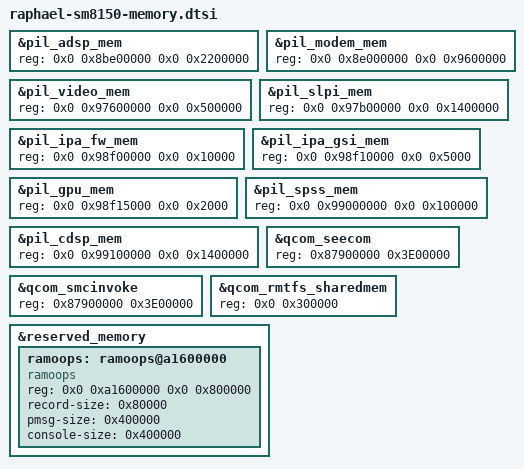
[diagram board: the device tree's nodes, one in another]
/* Copyright (c) 2020, The Linux Foundation. All rights reserved.
 *
 * This program is free software; you can redistribute it and/or modify
 * it under the terms of the GNU General Public License version 2 and
 * only version 2 as published by the Free Software Foundation.
 *
 * This program is distributed in the hope that it will be useful,
 * but WITHOUT ANY WARRANTY; without even the implied warranty of
 * MERCHANTABILITY or FITNESS FOR A PARTICULAR PURPOSE.  See the
 * GNU General Public License for more details.
 */

&pil_adsp_mem {
	reg = <0x0 0x8be00000 0x0 0x2200000>;
};

&pil_modem_mem {
	reg = <0x0 0x8e000000 0x0 0x9600000>;
};

&pil_video_mem {
	reg = <0x0 0x97600000 0x0 0x500000>;
};

&pil_slpi_mem {
	reg = <0x0 0x97b00000 0x0 0x1400000>;
};

&pil_ipa_fw_mem {
	reg = <0x0 0x98f00000 0x0 0x10000>;
};

&pil_ipa_gsi_mem {
	reg = <0x0 0x98f10000 0x0 0x5000>;
};

&pil_gpu_mem {
	reg = <0x0 0x98f15000 0x0 0x2000>;
};

&pil_spss_mem {
	reg = <0x0 0x99000000 0x0 0x100000>;
};

&pil_cdsp_mem {
	reg = <0x0 0x99100000 0x0 0x1400000>;
};

&qcom_seecom {
	reg = <0x87900000 0x3E00000>;
};

&qcom_smcinvoke {
	reg = <0x87900000 0x3E00000>;
};

&qcom_rmtfs_sharedmem {
	reg = <0x0 0x300000>;
};

&reserved_memory {
	/delete-node/ disp_rdump_region;
	ramoops: ramoops@a1600000 {
		compatible = "ramoops";
		reg = <0x0 0xa1600000 0x0 0x800000>;
		record-size = <0x80000>;
		pmsg-size = <0x400000>;
		console-size = <0x400000>;
	};
};
